# TC37X register map
File version: 1.0.0
CPU: CM4 r0p1, little endian, MPU, FPU, VTOR, 3 interrupt priority bits
Registers are 16-bit, read-write, reset 0x0 unless marked. A register's access mark holds for its fields unless they carry their own. Offsets are from the block's base; [hi:lo] are bit positions; {n}, {i} and the like mark numbered series.

## port_34 — eneral Purpose I/O Ports and Peripheral I/O Lines
Base 0xF003C200
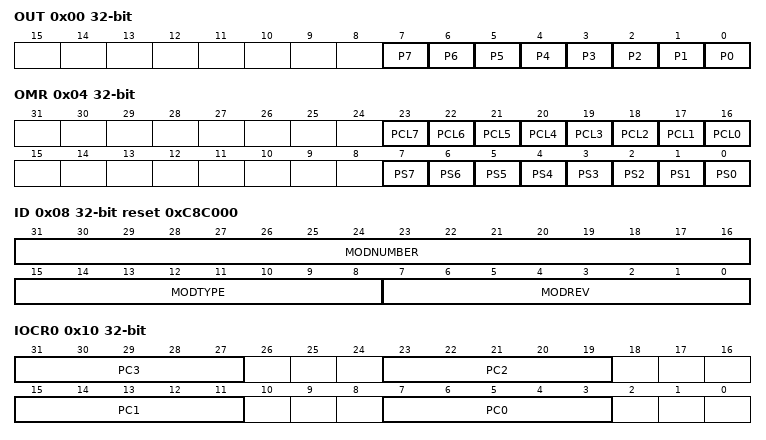
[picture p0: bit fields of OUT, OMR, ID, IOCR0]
0x00 OUT 32-bit — Port 34 Output Register
  [n] P{n} (n=0..7) — Output Bit {n}
0x04 OMR 32-bit — Port 34 Output Modification Register
  [n+16] PCL{n} wo (n=0..7) — Clear Bit {n}
  [n] PS{n} wo (n=0..7) — Set Bit {n}
0x08 ID 32-bit ro reset 0xC8C000 (reset mask 0xFFFFFF00) — Port 34 Identification Register
  [31:16] MODNUMBER — Module Number
  [15:8] MODTYPE — Module Type
  [7:0] MODREV — Module Revision Number
0x10 IOCR0 32-bit — Port 34 Input/Output Control Register 0
  [8n+7:8n+3] PC{n} (n=0..3) — Port Control for Pin {n}
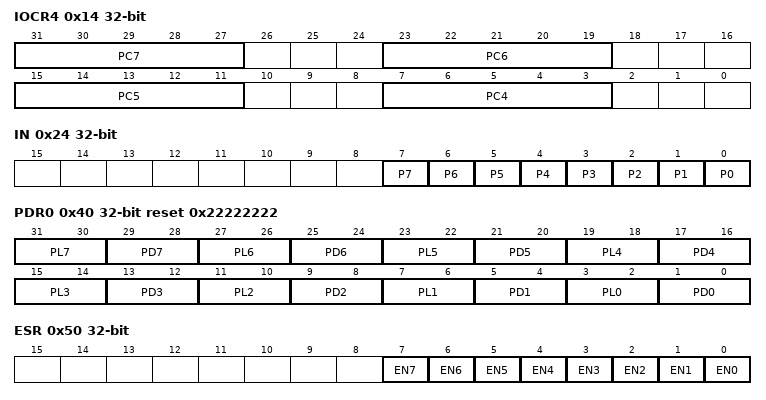
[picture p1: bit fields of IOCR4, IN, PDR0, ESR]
0x14 IOCR4 32-bit — Port 34 Input/Output Control Register 4
  [8n-25:8n-29] PC{n} (n=4..7) — Port Control for Port 34 Pin {n}
0x24 IN 32-bit ro (reset mask 0xFFFFFF00) — Port 34 Input Register
  [n] P{n} (n=0..7) — Input Bit {n}
0x40 PDR0 32-bit reset 0x22222222 — Port 34 Pad Driver Mode Register 0
  [4n+3:4n+2] PL{n} (n=0..7) — Pad Level Selection for Pin {n}
  [4n+1:4n] PD{n} (n=0..7) — Pad Driver Mode for Pin {n}
0x50 ESR 32-bit — Port 34 Emergency Stop Register
  [n] EN{n} (n=0..7) — Emergency Stop Enable for Pin {n}
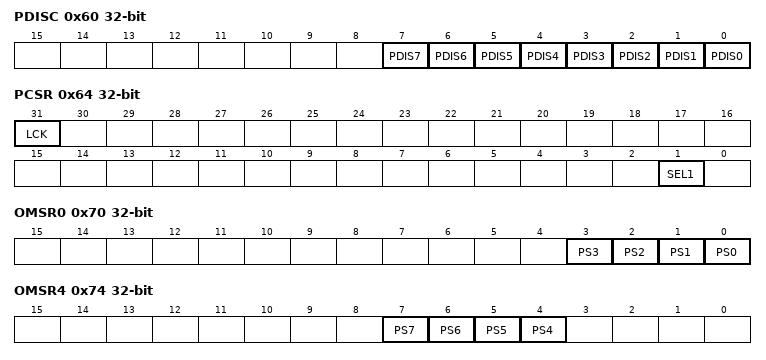
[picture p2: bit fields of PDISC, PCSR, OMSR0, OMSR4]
0x60 PDISC 32-bit — Port 34 Pin Function Decision Control Register
  [n] PDIS{n} (n=0..7) — Pin Function Decision Control for Pin {n}
0x64 PCSR 32-bit — Port 34 Pin Controller Select Register
  [31] LCK ro — Lock Status
  [1] SEL1 — Output Select for Pin 1
0x70 OMSR0 32-bit — Port 34 Output Modification Set Register 0
  [n] PS{n} wo (n=0..3) — Set Bit {n}
0x74 OMSR4 32-bit — Port 34 Output Modification Set Register 4
  [n] PS{n} wo (n=4..7) — Set Bit {n}
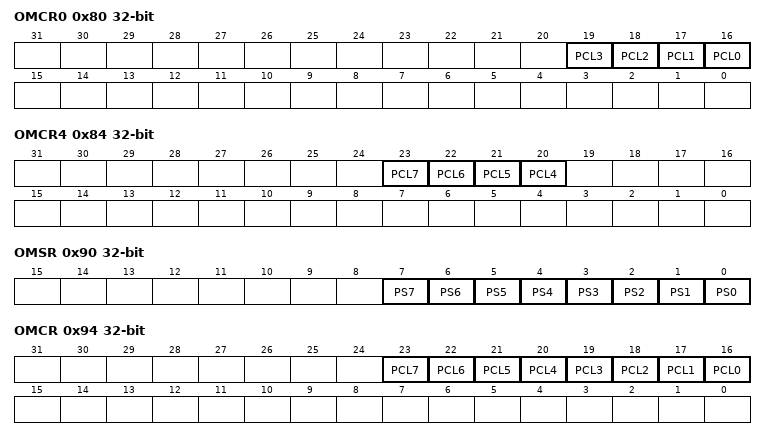
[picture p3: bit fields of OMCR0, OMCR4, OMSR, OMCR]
0x80 OMCR0 32-bit — Port 34 Output Modification Clear Register 0
  [n+16] PCL{n} wo (n=0..3) — Clear Bit {n}
0x84 OMCR4 32-bit — Port 34 Output Modification Clear Register 4
  [n+16] PCL{n} wo (n=4..7) — Clear Bit {n}
0x90 OMSR 32-bit — Port 34 Output Modification Set Register
  [n] PS{n} wo (n=0..7) — Set Bit {n}
0x94 OMCR 32-bit — Port 34 Output Modification Clear Register
  [n+16] PCL{n} wo (n=0..7) — Clear Bit {n}
0xF8 ACCEN1 32-bit ro — Port 34 Access Enable Register 1
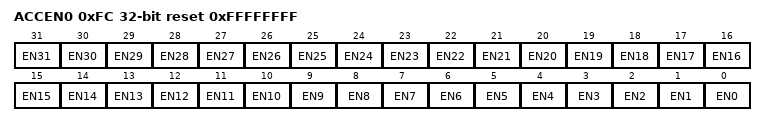
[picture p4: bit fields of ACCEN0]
0xFC ACCEN0 32-bit reset 0xFFFFFFFF — Port 34 Access Enable Register 0
  [n] EN{n} (n=0..31) — Access Enable for Master TAG ID {n}

## port_40 — eneral Purpose I/O Ports and Peripheral I/O Lines
Base 0xF003C800
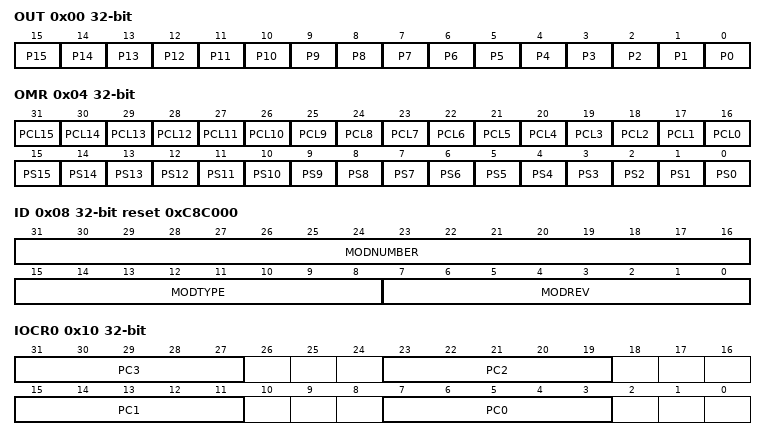
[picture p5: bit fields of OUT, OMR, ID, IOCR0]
0x00 OUT 32-bit — Port 40 Output Register
  [n] P{n} (n=0..15) — Output Bit {n}
0x04 OMR 32-bit wo — Port 40 Output Modification Register
  [n+16] PCL{n} (n=0..15) — Clear Bit {n}
  [n] PS{n} (n=0..15) — Set Bit {n}
0x08 ID 32-bit ro reset 0xC8C000 (reset mask 0xFFFFFF00) — Port 40 Identification Register
  [31:16] MODNUMBER — Module Number
  [15:8] MODTYPE — Module Type
  [7:0] MODREV — Module Revision Number
0x10 IOCR0 32-bit — Port 40 Input/Output Control Register 0
  [8n+7:8n+3] PC{n} (n=0..3) — Port Control for Pin {n}
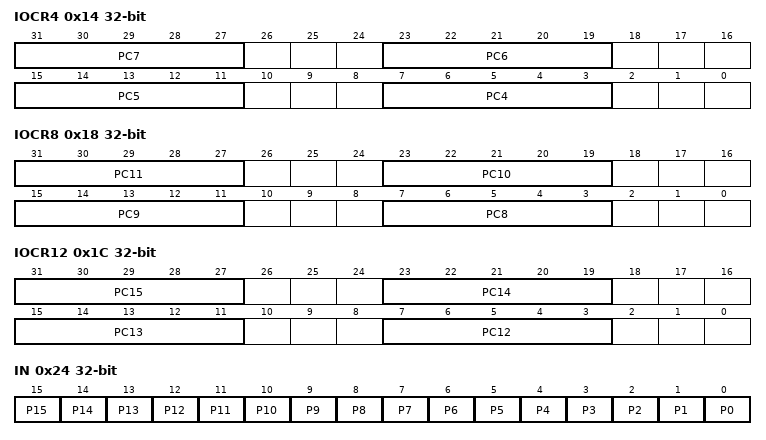
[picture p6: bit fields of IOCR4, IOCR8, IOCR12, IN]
0x14 IOCR4 32-bit — Port 40 Input/Output Control Register 4
  [8n-25:8n-29] PC{n} (n=4..7) — Port Control for Port 40 Pin {n}
0x18 IOCR8 32-bit — Port 40 Input/Output Control Register 8
  [8n-57:8n-61] PC{n} (n=8..11) — Port Control for Port 40 Pin {n}
0x1C IOCR12 32-bit — Port 40 Input/Output Control Register 12
  [8n-89:8n-93] PC{n} (n=12..15) — Port Control for Port 40 Pin {n}
0x24 IN 32-bit ro (reset mask 0xFFFF0000) — Port 40 Input Register
  [n] P{n} (n=0..15) — Input Bit {n}
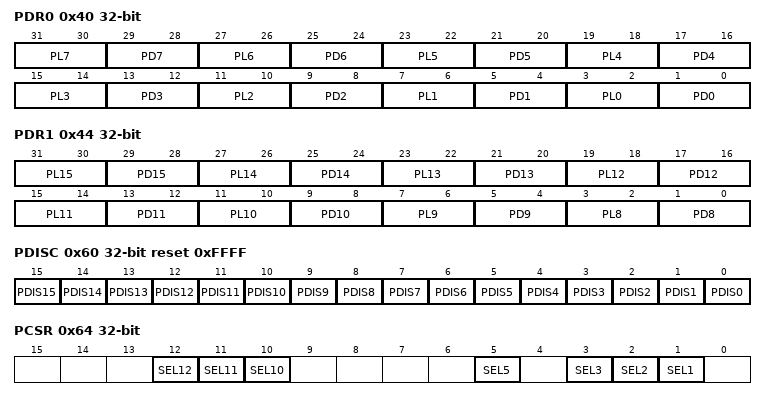
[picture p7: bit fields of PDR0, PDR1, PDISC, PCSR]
0x40 PDR0 32-bit — Port 40 Pad Driver Mode Register 0
  [4n+3:4n+2] PL{n} (n=0..7) — Pad Level Selection for Pin {n}
  [4n+1:4n] PD{n} (n=0..7) — Pad Driver Mode for Pin {n}
0x44 PDR1 32-bit — Port 40 Pad Driver Mode Register 1
  [4n-29:4n-30] PL{n} (n=8..15) — Pad Level Selection for Pin {n}
  [4n-31:4n-32] PD{n} (n=8..15) — Pad Driver Mode for Pin {n}
0x50 ESR 32-bit ro — Port 40 Emergency Stop Register
0x60 PDISC 32-bit reset 0xFFFF — Port 40 Pin Function Decision Control Register
  [n] PDIS{n} (n=0..15) — Pin Function Decision Control for Pin {n}
0x64 PCSR 32-bit — Port 40 Pin Controller Select Register
  [12] SEL12 — Output Select for Pin 12
  [11] SEL11 — Output Select for Pin 11
  [10] SEL10 — Output Select for Pin 10
  [5] SEL5 — Output Select for Pin 5
  [3] SEL3 — Output Select for Pin 3
  [2] SEL2 — Output Select for Pin 2
  [1] SEL1 — Output Select for Pin 1
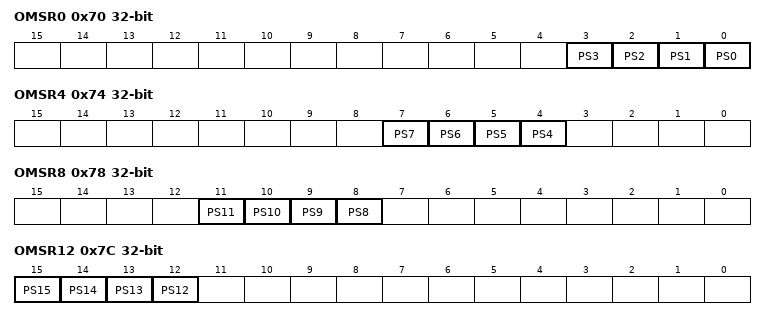
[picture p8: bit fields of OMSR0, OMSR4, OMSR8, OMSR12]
0x70 OMSR0 32-bit — Port 40 Output Modification Set Register 0
  [n] PS{n} wo (n=0..3) — Set Bit {n}
0x74 OMSR4 32-bit — Port 40 Output Modification Set Register 4
  [n] PS{n} wo (n=4..7) — Set Bit {n}
0x78 OMSR8 32-bit — Port 40 Output Modification Set Register 8
  [n] PS{n} wo (n=8..11) — Set Bit {n}
0x7C OMSR12 32-bit — Port 40 Output Modification Set Register 12
  [n] PS{n} wo (n=12..15) — Set Bit {n}
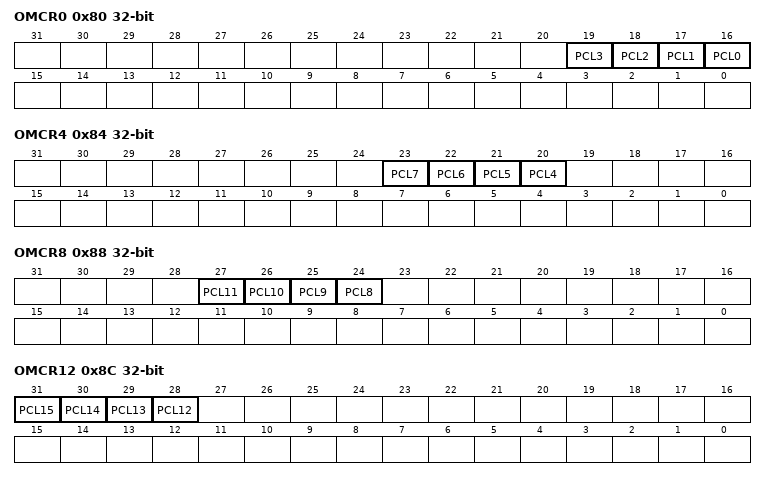
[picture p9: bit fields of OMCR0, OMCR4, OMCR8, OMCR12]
0x80 OMCR0 32-bit — Port 40 Output Modification Clear Register 0
  [n+16] PCL{n} wo (n=0..3) — Clear Bit {n}
0x84 OMCR4 32-bit — Port 40 Output Modification Clear Register 4
  [n+16] PCL{n} wo (n=4..7) — Clear Bit {n}
0x88 OMCR8 32-bit — Port 40 Output Modification Clear Register 8
  [n+16] PCL{n} wo (n=8..11) — Clear Bit {n}
0x8C OMCR12 32-bit — Port 40 Output Modification Clear Register 12
  [n+16] PCL{n} wo (n=12..15) — Clear Bit {n}
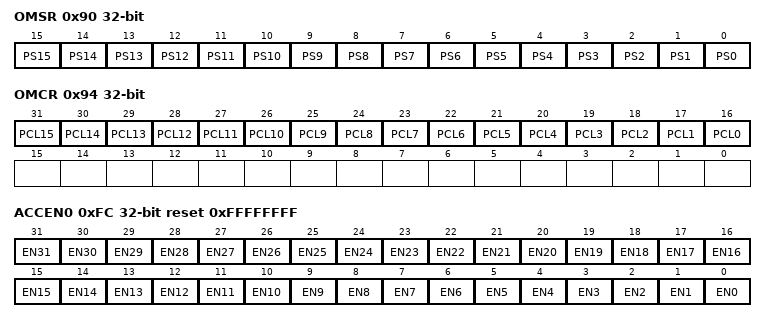
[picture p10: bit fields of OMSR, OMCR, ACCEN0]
0x90 OMSR 32-bit — Port 40 Output Modification Set Register
  [n] PS{n} wo (n=0..15) — Set Bit {n}
0x94 OMCR 32-bit — Port 40 Output Modification Clear Register
  [n+16] PCL{n} wo (n=0..15) — Clear Bit {n}
0xF8 ACCEN1 32-bit ro — Port 40 Access Enable Register 1
0xFC ACCEN0 32-bit reset 0xFFFFFFFF — Port 40 Access Enable Register 0
  [n] EN{n} (n=0..31) — Access Enable for Master TAG ID {n}
